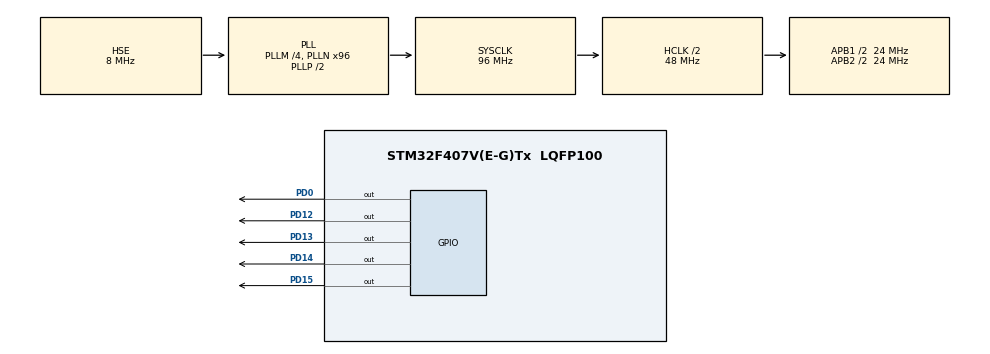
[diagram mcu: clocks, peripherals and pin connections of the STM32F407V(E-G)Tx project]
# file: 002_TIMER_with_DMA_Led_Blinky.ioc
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Dma.Request0=TIM1_UP
Dma.TIM1_UP.0.Direction=DMA_MEMORY_TO_PERIPH
Dma.TIM1_UP.0.FIFOMode=DMA_FIFOMODE_DISABLE
Dma.TIM1_UP.0.Instance=DMA2_Stream5
Dma.TIM1_UP.0.MemDataAlignment=DMA_MDATAALIGN_WORD
Dma.TIM1_UP.0.MemInc=DMA_MINC_ENABLE
Dma.TIM1_UP.0.Mode=DMA_CIRCULAR
Dma.TIM1_UP.0.PeriphDataAlignment=DMA_PDATAALIGN_WORD
Dma.TIM1_UP.0.PeriphInc=DMA_PINC_DISABLE
Dma.TIM1_UP.0.Priority=DMA_PRIORITY_LOW
Mcu.Family=STM32F4
Mcu.Name=STM32F407V(E-G)Tx
Mcu.Package=LQFP100
NVIC.DMA2_Stream5_IRQn=true\:0\:0\:false\:false\:true\:false\:true
NVIC.PriorityGroup=NVIC_PRIORITYGROUP_0
PD0.Signal=GPIO_Output
PD12.Signal=GPIO_Output
PD13.Signal=GPIO_Output
PD14.Signal=GPIO_Output
PD15.Signal=GPIO_Output
PH0-OSC_IN.Mode=HSE-External-Oscillator
PH0-OSC_IN.Signal=RCC_OSC_IN
PH1-OSC_OUT.Mode=HSE-External-Oscillator
PH1-OSC_OUT.Signal=RCC_OSC_OUT
ProjectManager.HeapSize=0x200
ProjectManager.StackSize=0x400
ProjectManager.TargetToolchain=STM32CubeIDE
RCC.48MHZClocksFreq_Value=27428571.42857143
RCC.AHBCLKDivider=RCC_SYSCLK_DIV2
RCC.AHBFreq_Value=48000000
RCC.APB1CLKDivider=RCC_HCLK_DIV2
RCC.APB1Freq_Value=24000000
RCC.APB1TimFreq_Value=48000000
RCC.APB2CLKDivider=RCC_HCLK_DIV2
RCC.APB2Freq_Value=24000000
RCC.APB2TimFreq_Value=48000000
RCC.CortexFreq_Value=48000000
RCC.EnbaleCSS=true
RCC.HCLKFreq_Value=48000000
RCC.HSE_VALUE=8000000
RCC.HSI_VALUE=16000000
RCC.LSE_VALUE=32768
RCC.PLLM=4
RCC.PLLN=96
RCC.PLLQ=7
RCC.PLLSourceVirtual=RCC_PLLSOURCE_HSE
RCC.SYSCLKFreq_VALUE=96000000
RCC.SYSCLKSource=RCC_SYSCLKSOURCE_PLLCLK
RCC.VCOOutputFreq_Value=192000000
TIM1.AutoReloadPreload=TIM_AUTORELOAD_PRELOAD_ENABLE
TIM1.ClockDivision=TIM_CLOCKDIVISION_DIV1
TIM1.Period=499
TIM1.Prescaler=47999
VP_TIM1_VS_ClockSourceINT.Mode=Internal
board=STM32F407G-DISC1

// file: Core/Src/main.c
/* USER CODE BEGIN Header */
/**
  ******************************************************************************
  * @file           : main.c
  * @brief          : Main program body
  ******************************************************************************
  * @attention
  *
  * Copyright (c) 2021 STMicroelectronics.
  * All rights reserved.
  *
  * This software is licensed under terms that can be found in the LICENSE file
  * in the root directory of this software component.
  * If no LICENSE file comes with this software, it is provided AS-IS.
  *
  ******************************************************************************
  */
/* USER CODE END Header */
#include "main.h"

TIM_HandleTypeDef htim1;
DMA_HandleTypeDef hdma_tim1_up;

void SystemClock_Config(void);
static void MX_GPIO_Init(void);
static void MX_DMA_Init(void);
static void MX_TIM1_Init(void);

int main(void)
{
  /* USER CODE BEGIN 1 */
	uint32_t data[] = {0xFFFF, 0x0};
  /* USER CODE END 1 */

  /* MCU Configuration--------------------------------------------------------*/

  /* Reset of all peripherals, Initializes the Flash interface and the Systick. */
  HAL_Init();

  /* Configure the system clock */
  SystemClock_Config();

  /* Initialize all configured peripherals */
  MX_GPIO_Init();
  MX_DMA_Init();
  MX_TIM1_Init();
  /* USER CODE BEGIN 2 */

  HAL_TIM_Base_Start(&htim1);
  HAL_DMA_Start(&hdma_tim1_up,(uint32_t)data,(uint32_t)&GPIOD->ODR, 2);
   __HAL_TIM_ENABLE_DMA(&htim1,TIM_DMA_UPDATE);
  /* USER CODE END 2 */

  /* Infinite loop */
  while (1)
  {

  }
}

void SystemClock_Config(void)
{
  RCC_OscInitTypeDef RCC_OscInitStruct = {0};
  RCC_ClkInitTypeDef RCC_ClkInitStruct = {0};

  /** Configure the main internal regulator output voltage
  */
  __HAL_RCC_PWR_CLK_ENABLE();
  __HAL_PWR_VOLTAGESCALING_CONFIG(PWR_REGULATOR_VOLTAGE_SCALE1);
  /** Initializes the RCC Oscillators according to the specified parameters
  * in the RCC_OscInitTypeDef structure.
  */
  RCC_OscInitStruct.OscillatorType = RCC_OSCILLATORTYPE_HSE;
  RCC_OscInitStruct.HSEState = RCC_HSE_ON;
  RCC_OscInitStruct.PLL.PLLState = RCC_PLL_ON;
  RCC_OscInitStruct.PLL.PLLSource = RCC_PLLSOURCE_HSE;
  RCC_OscInitStruct.PLL.PLLM = 4;
  RCC_OscInitStruct.PLL.PLLN = 96;
  RCC_OscInitStruct.PLL.PLLP = RCC_PLLP_DIV2;
  RCC_OscInitStruct.PLL.PLLQ = 7;
  if (HAL_RCC_OscConfig(&RCC_OscInitStruct) != HAL_OK)
  {
    Error_Handler();
  }
  /** Initializes the CPU, AHB and APB buses clocks
  */
  RCC_ClkInitStruct.ClockType = RCC_CLOCKTYPE_HCLK|RCC_CLOCKTYPE_SYSCLK
                              |RCC_CLOCKTYPE_PCLK1|RCC_CLOCKTYPE_PCLK2;
  RCC_ClkInitStruct.SYSCLKSource = RCC_SYSCLKSOURCE_PLLCLK;
  RCC_ClkInitStruct.AHBCLKDivider = RCC_SYSCLK_DIV2;
  RCC_ClkInitStruct.APB1CLKDivider = RCC_HCLK_DIV2;
  RCC_ClkInitStruct.APB2CLKDivider = RCC_HCLK_DIV2;

  if (HAL_RCC_ClockConfig(&RCC_ClkInitStruct, FLASH_LATENCY_1) != HAL_OK)
  {
    Error_Handler();
  }
  /** Enables the Clock Security System
  */
  HAL_RCC_EnableCSS();
}

static void MX_TIM1_Init(void)
{

  TIM_ClockConfigTypeDef sClockSourceConfig = {0};
  TIM_MasterConfigTypeDef sMasterConfig = {0};

  htim1.Instance = TIM1;
  htim1.Init.Prescaler = 47999;
  htim1.Init.CounterMode = TIM_COUNTERMODE_UP;
  htim1.Init.Period = 499;
  htim1.Init.ClockDivision = TIM_CLOCKDIVISION_DIV1;
  htim1.Init.RepetitionCounter = 0;
  htim1.Init.AutoReloadPreload = TIM_AUTORELOAD_PRELOAD_ENABLE;
  if (HAL_TIM_Base_Init(&htim1) != HAL_OK)
  {
    Error_Handler();
  }
  sClockSourceConfig.ClockSource = TIM_CLOCKSOURCE_INTERNAL;
  if (HAL_TIM_ConfigClockSource(&htim1, &sClockSourceConfig) != HAL_OK)
  {
    Error_Handler();
  }
  sMasterConfig.MasterOutputTrigger = TIM_TRGO_RESET;
  sMasterConfig.MasterSlaveMode = TIM_MASTERSLAVEMODE_DISABLE;
  if (HAL_TIMEx_MasterConfigSynchronization(&htim1, &sMasterConfig) != HAL_OK)
  {
    Error_Handler();
  }

}

static void MX_DMA_Init(void)
{

  /* DMA controller clock enable */
  __HAL_RCC_DMA2_CLK_ENABLE();

  /* DMA interrupt init */
  /* DMA2_Stream5_IRQn interrupt configuration */
  HAL_NVIC_SetPriority(DMA2_Stream5_IRQn, 0, 0);
  HAL_NVIC_EnableIRQ(DMA2_Stream5_IRQn);

}

static void MX_GPIO_Init(void)
{
  GPIO_InitTypeDef GPIO_InitStruct = {0};

  /* GPIO Ports Clock Enable */
  __HAL_RCC_GPIOH_CLK_ENABLE();
  __HAL_RCC_GPIOD_CLK_ENABLE();

  /*Configure GPIO pin Output Level */
  HAL_GPIO_WritePin(GPIOD, GPIO_PIN_12|GPIO_PIN_13|GPIO_PIN_14|GPIO_PIN_15
                          |GPIO_PIN_0, GPIO_PIN_RESET);

  /*Configure GPIO pins : PD12 PD13 PD14 PD15
                           PD0 */
  GPIO_InitStruct.Pin = GPIO_PIN_12|GPIO_PIN_13|GPIO_PIN_14|GPIO_PIN_15
                          |GPIO_PIN_0;
  GPIO_InitStruct.Mode = GPIO_MODE_OUTPUT_PP;
  GPIO_InitStruct.Pull = GPIO_NOPULL;
  GPIO_InitStruct.Speed = GPIO_SPEED_FREQ_LOW;
  HAL_GPIO_Init(GPIOD, &GPIO_InitStruct);

}

void Error_Handler(void)
{
  __disable_irq();
  while (1)
  {
  }
}
